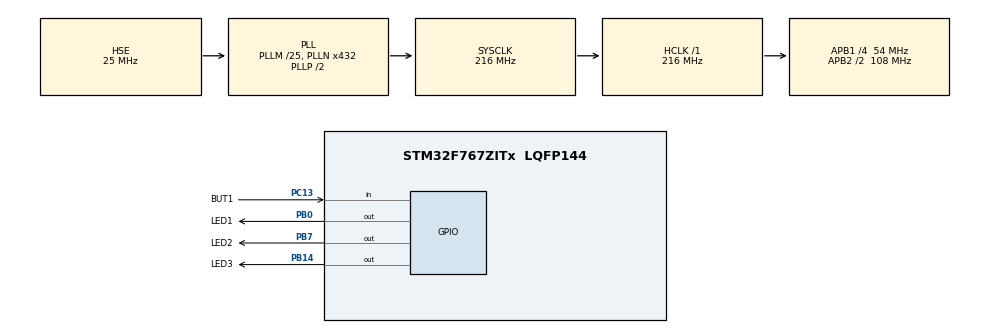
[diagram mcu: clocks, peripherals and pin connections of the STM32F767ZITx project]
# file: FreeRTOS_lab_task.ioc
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FREERTOS.Tasks01=defaultTask,24,128,StartDefaultTask,Default,NULL,Dynamic,NULL,NULL;LED1_Task,24,128,StartLED1_Task,Default,NULL,Dynamic,NULL,NULL;LED2_Task,24,128,StartLED2_Task,Default,NULL,Dynamic,NULL,NULL;BUT1_Task,24,128,StartBUT1_Task,Default,NULL,Dynamic,NULL,NULL;LED3_Task,24,128,StartLED3_Task,Default,NULL,Dynamic,NULL,NULL
FREERTOS.configUSE_NEWLIB_REENTRANT=1
Mcu.Family=STM32F7
Mcu.Name=STM32F767ZITx
Mcu.Package=LQFP144
NVIC.PriorityGroup=NVIC_PRIORITYGROUP_4
NVIC.TIM6_DAC_IRQn=true\:15\:0\:false\:false\:true\:false\:false\:true\:true
NVIC.TimeBase=TIM6_DAC_IRQn
NVIC.TimeBaseIP=TIM6
PA13.Mode=Serial_Wire
PA13.Signal=SYS_JTMS-SWDIO
PA14.Mode=Serial_Wire
PA14.Signal=SYS_JTCK-SWCLK
PB0.GPIO_Label=LED1
PB0.Signal=GPIO_Output
PB14.GPIO_Label=LED3
PB14.Signal=GPIO_Output
PB7.GPIO_FM7=SYSCFG_PMC_I2C_PB7_FMP
PB7.GPIO_Label=LED2
PB7.Signal=GPIO_Output
PC13.GPIO_Label=BUT1
PC13.GPIO_PuPd=GPIO_NOPULL
PC13.Signal=GPIO_Input
PH0/OSC_IN.Mode=HSE-External-Oscillator
PH0/OSC_IN.Signal=RCC_OSC_IN
PH1/OSC_OUT.Mode=HSE-External-Oscillator
PH1/OSC_OUT.Signal=RCC_OSC_OUT
ProjectManager.HeapSize=0x200
ProjectManager.StackSize=0x400
ProjectManager.TargetToolchain=STM32CubeIDE
RCC.AHBFreq_Value=216000000
RCC.APB1CLKDivider=RCC_HCLK_DIV4
RCC.APB1Freq_Value=54000000
RCC.APB1TimFreq_Value=108000000
RCC.APB2CLKDivider=RCC_HCLK_DIV2
RCC.APB2Freq_Value=108000000
RCC.APB2TimFreq_Value=216000000
RCC.CortexFreq_Value=216000000
RCC.HCLKFreq_Value=216000000
RCC.HSE_VALUE=25000000
RCC.HSI_VALUE=16000000
RCC.LSE_VALUE=32768
RCC.PLLM=25
RCC.PLLN=432
RCC.PLLSourceVirtual=RCC_PLLSOURCE_HSE
RCC.SYSCLKFreq_VALUE=216000000
RCC.SYSCLKSource=RCC_SYSCLKSOURCE_PLLCLK
RCC.USBFreq_Value=216000000
RCC.VCOOutputFreq_Value=432000000
VP_FREERTOS_VS_CMSIS_V2.Mode=CMSIS_V2
VP_SYS_VS_tim6.Mode=TIM6
board=custom

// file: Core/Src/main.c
/* USER CODE BEGIN Header */
/**
  ******************************************************************************
  * @file           : main.c
  * @brief          : Main program body
  ******************************************************************************
  * @attention
  *
  * Copyright (c) 2023 STMicroelectronics.
  * All rights reserved.
  *
  * This software is licensed under terms that can be found in the LICENSE file
  * in the root directory of this software component.
  * If no LICENSE file comes with this software, it is provided AS-IS.
  *
  ******************************************************************************
  */
/* USER CODE END Header */
#include "main.h"
#include "cmsis_os.h"
#include "gpio.h"

void SystemClock_Config(void);
void MX_FREERTOS_Init(void);

int main(void)
{

  /* MCU Configuration--------------------------------------------------------*/

  /* Reset of all peripherals, Initializes the Flash interface and the Systick. */
  HAL_Init();

  /* Configure the system clock */
  SystemClock_Config();

  /* Initialize all configured peripherals */
  MX_GPIO_Init();

  /* Init scheduler */
  osKernelInitialize();  /* Call init function for freertos objects (in freertos.c) */
  MX_FREERTOS_Init();

  /* Start scheduler */
  osKernelStart();

  /* We should never get here as control is now taken by the scheduler */
  /* Infinite loop */
  while (1)
  {

  }
}

void SystemClock_Config(void)
{
  RCC_OscInitTypeDef RCC_OscInitStruct = {0};
  RCC_ClkInitTypeDef RCC_ClkInitStruct = {0};

  /** Configure the main internal regulator output voltage
  */
  __HAL_RCC_PWR_CLK_ENABLE();
  __HAL_PWR_VOLTAGESCALING_CONFIG(PWR_REGULATOR_VOLTAGE_SCALE1);

  /** Initializes the RCC Oscillators according to the specified parameters
  * in the RCC_OscInitTypeDef structure.
  */
  RCC_OscInitStruct.OscillatorType = RCC_OSCILLATORTYPE_HSE;
  RCC_OscInitStruct.HSEState = RCC_HSE_ON;
  RCC_OscInitStruct.PLL.PLLState = RCC_PLL_ON;
  RCC_OscInitStruct.PLL.PLLSource = RCC_PLLSOURCE_HSE;
  RCC_OscInitStruct.PLL.PLLM = 25;
  RCC_OscInitStruct.PLL.PLLN = 432;
  RCC_OscInitStruct.PLL.PLLP = RCC_PLLP_DIV2;
  RCC_OscInitStruct.PLL.PLLQ = 2;
  RCC_OscInitStruct.PLL.PLLR = 2;
  if (HAL_RCC_OscConfig(&RCC_OscInitStruct) != HAL_OK)
  {
    Error_Handler();
  }

  /** Activate the Over-Drive mode
  */
  if (HAL_PWREx_EnableOverDrive() != HAL_OK)
  {
    Error_Handler();
  }

  /** Initializes the CPU, AHB and APB buses clocks
  */
  RCC_ClkInitStruct.ClockType = RCC_CLOCKTYPE_HCLK|RCC_CLOCKTYPE_SYSCLK
                              |RCC_CLOCKTYPE_PCLK1|RCC_CLOCKTYPE_PCLK2;
  RCC_ClkInitStruct.SYSCLKSource = RCC_SYSCLKSOURCE_PLLCLK;
  RCC_ClkInitStruct.AHBCLKDivider = RCC_SYSCLK_DIV1;
  RCC_ClkInitStruct.APB1CLKDivider = RCC_HCLK_DIV4;
  RCC_ClkInitStruct.APB2CLKDivider = RCC_HCLK_DIV2;

  if (HAL_RCC_ClockConfig(&RCC_ClkInitStruct, FLASH_LATENCY_7) != HAL_OK)
  {
    Error_Handler();
  }
}

void HAL_TIM_PeriodElapsedCallback(TIM_HandleTypeDef *htim)
{
  if (htim->Instance == TIM6) {
    HAL_IncTick();
  }
}

void Error_Handler(void)
{
  __disable_irq();
  while (1)
  {
  }
}

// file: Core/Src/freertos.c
/* USER CODE BEGIN Header */
/**
  ******************************************************************************
  * File Name          : freertos.c
  * Description        : Code for freertos applications
  ******************************************************************************
  * @attention
  *
  * Copyright (c) 2023 STMicroelectronics.
  * All rights reserved.
  *
  * This software is licensed under terms that can be found in the LICENSE file
  * in the root directory of this software component.
  * If no LICENSE file comes with this software, it is provided AS-IS.
  *
  ******************************************************************************
  */
/* USER CODE END Header */

#include "FreeRTOS.h"
#include "task.h"
#include "main.h"
#include "cmsis_os.h"

/* USER CODE BEGIN Variables */
GPIO_PinState ButtonStateCurrent;
GPIO_PinState ButtonStateLast = GPIO_PIN_RESET;

/* USER CODE END Variables */
/* Definitions for defaultTask */
osThreadId_t defaultTaskHandle;
const osThreadAttr_t defaultTask_attributes = {
  .name = "defaultTask",
  .stack_size = 128 * 4,
  .priority = (osPriority_t) osPriorityNormal,
};
/* Definitions for LED1_Task */
osThreadId_t LED1_TaskHandle;
const osThreadAttr_t LED1_Task_attributes = {
  .name = "LED1_Task",
  .stack_size = 128 * 4,
  .priority = (osPriority_t) osPriorityNormal,
};
/* Definitions for LED2_Task */
osThreadId_t LED2_TaskHandle;
const osThreadAttr_t LED2_Task_attributes = {
  .name = "LED2_Task",
  .stack_size = 128 * 4,
  .priority = (osPriority_t) osPriorityNormal,
};
/* Definitions for BUT1_Task */
osThreadId_t BUT1_TaskHandle;
const osThreadAttr_t BUT1_Task_attributes = {
  .name = "BUT1_Task",
  .stack_size = 128 * 4,
  .priority = (osPriority_t) osPriorityNormal,
};
/* Definitions for LED3_Task */
osThreadId_t LED3_TaskHandle;
const osThreadAttr_t LED3_Task_attributes = {
  .name = "LED3_Task",
  .stack_size = 128 * 4,
  .priority = (osPriority_t) osPriorityNormal,
};

void StartDefaultTask(void *argument);
void StartLED1_Task(void *argument);
void StartLED2_Task(void *argument);
void StartBUT1_Task(void *argument);
void StartLED3_Task(void *argument);

void MX_FREERTOS_Init(void); /* (MISRA C 2004 rule 8.1) */

void MX_FREERTOS_Init(void) {

  /* Create the thread(s) */
  /* creation of defaultTask */
  defaultTaskHandle = osThreadNew(StartDefaultTask, NULL, &defaultTask_attributes);

  /* creation of LED1_Task */
  LED1_TaskHandle = osThreadNew(StartLED1_Task, NULL, &LED1_Task_attributes);

  /* creation of LED2_Task */
  LED2_TaskHandle = osThreadNew(StartLED2_Task, NULL, &LED2_Task_attributes);

  /* creation of BUT1_Task */
  BUT1_TaskHandle = osThreadNew(StartBUT1_Task, NULL, &BUT1_Task_attributes);

  /* creation of LED3_Task */
  LED3_TaskHandle = osThreadNew(StartLED3_Task, NULL, &LED3_Task_attributes);

}

void StartDefaultTask(void *argument)
{
  for(;;)
  {
    osDelay(1);
  }
}

void StartLED1_Task(void *argument)
{
  /* USER CODE BEGIN StartLED1_Task */
  /* Infinite loop */
  for(;;)
  {
	  if(ButtonStateCurrent == ButtonStateLast)
	  {
		  HAL_GPIO_TogglePin(LED1_GPIO_Port, LED1_Pin);
		  osDelay(100);
	  }
  }
  /* USER CODE END StartLED1_Task */
}

void StartLED2_Task(void *argument)
{
  /* USER CODE BEGIN StartLED2_Task */
  /* Infinite loop */
  for(;;)
  {
	  HAL_GPIO_TogglePin(LED2_GPIO_Port, LED2_Pin);
	  osDelay(300);
  }
  /* USER CODE END StartLED2_Task */
}

void StartBUT1_Task(void *argument)
{
  /* USER CODE BEGIN StartBUT1_Task */
  /* Infinite loop */
  for(;;)
  {
	  ButtonStateCurrent = HAL_GPIO_ReadPin(BUT1_GPIO_Port, BUT1_Pin);
  }
  /* USER CODE END StartBUT1_Task */
}

void StartLED3_Task(void *argument)
{
  /* USER CODE BEGIN StartLED3_Task */
  /* Infinite loop */
  for(;;)
  {
	  HAL_GPIO_TogglePin(LED3_GPIO_Port, LED3_Pin);
	  osDelay(900);
  }
  /* USER CODE END StartLED3_Task */
}
